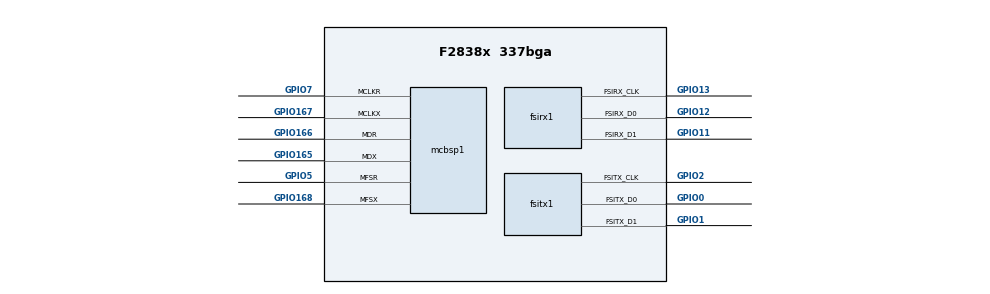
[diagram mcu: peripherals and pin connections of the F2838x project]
/**
 * @cliArgs --device "F2838x" --part "F2838x_337bga" --package "337bga" --context "CPU2" --product "C2000WARE@5.04.00.00"
 * @versions {"tool":"1.21.0+3721"}
 */

/**
 * Import the modules used in this configuration.
 */
const cputimer  = scripting.addModule("/driverlib/cputimer.js", {}, false);
const cputimer1 = cputimer.addInstance();
const dma       = scripting.addModule("/driverlib/dma.js", {}, false);
const dma1      = dma.addInstance();
const dma2      = dma.addInstance();
const flash     = scripting.addModule("/driverlib/flash.js", {}, false);
const flash1    = flash.addInstance();
const fsirx     = scripting.addModule("/driverlib/fsirx.js", {}, false);
const fsirx1    = fsirx.addInstance();
const fsitx     = scripting.addModule("/driverlib/fsitx.js", {}, false);
const fsitx1    = fsitx.addInstance();
const ipc       = scripting.addModule("/driverlib/ipc.js");
const mcbsp     = scripting.addModule("/driverlib/mcbsp.js", {}, false);
const mcbsp1    = mcbsp.addInstance();

/**
 * Write custom configuration values to the imported modules.
 */
cputimer1.$name          = "SWTIRMER";
cputimer1.cputimerBase   = "CPUTIMER1_BASE";
cputimer1.emulationMode  = "CPUTIMER_EMULATIONMODE_RUNFREE";
cputimer1.timerPrescaler = 3;
cputimer1.timerPeriod    = 50000000;
cputimer1.startTimer     = true;

dma1.$name = "DMA_FSI_TX";

dma2.$name   = "DMA_FSI_RX";
dma2.dmaBase = "DMA_CH2_BASE";

flash1.$name = "FMC_CPU2";

fsirx1.$name                      = "FSI_DAISY_RX";
fsirx1.dataWidth                  = "FSI_DATA_WIDTH_2_LANE";
fsirx1.softwareFrameSize          = "14";
fsirx1.fsirx.$assign              = "FSIRXA";
fsirx1.fsirx.fsirx_d0Pin.$assign  = "GPIO12";
fsirx1.fsirx.fsirx_d1Pin.$assign  = "GPIO11";
fsirx1.fsirx.fsirx_clkPin.$assign = "GPIO13";
fsirx1.d0Qual.$name               = "myGPIOQUAL4";
fsirx1.d1Qual.$name               = "myGPIOQUAL5";
fsirx1.clkQual.$name              = "myGPIOQUAL14";

fsitx1.$name                      = "FSI_DAISY_TX";
fsitx1.dataWidth                  = "FSI_DATA_WIDTH_2_LANE";
fsitx1.softwareFrameSize          = "14";
fsitx1.clkPres                    = 2;
fsitx1.fsitx.fsitx_d0Pin.$assign  = "GPIO0";
fsitx1.fsitx.fsitx_d1Pin.$assign  = "GPIO1";
fsitx1.fsitx.fsitx_clkPin.$assign = "GPIO2";
fsitx1.d0Qual.$name               = "myGPIOQUAL15";
fsitx1.d1Qual.$name               = "myGPIOQUAL16";
fsitx1.clkQual.$name              = "myGPIOQUAL17";

ipc.ipcRegisterFlag = ["IPC_FLAG31"];
ipc.flagHandler31   = "IPC_SYNC";

mcbsp1.$name                     = "McBSPA_CVAD_CCDA";
mcbsp1.txClockSource             = "MCBSP_INTERNAL_TX_CLOCK_SOURCE";
mcbsp1.txFrameSyncSource         = "MCBSP_TX_INTERNAL_FRAME_SYNC_SOURCE";
mcbsp1.txFrameSyncPolarity       = "MCBSP_TX_FRAME_SYNC_POLARITY_LOW";
mcbsp1.txDataDelayBits           = "MCBSP_DATA_DELAY_BIT_1";
mcbsp1.rxDataDelayBits           = "MCBSP_DATA_DELAY_BIT_1";
mcbsp1.clockStopMode             = "MCBSP_CLOCK_SPI_MODE_NO_DELAY";
mcbsp1.emulationMode             = "MCBSP_EMULATION_FREE_RUN";
mcbsp1.enableSampleRateGenerator = true;
mcbsp1.enableReceiver            = true;
mcbsp1.enableTransmitter         = true;
mcbsp1.srgDataClockDivider       = 7;
mcbsp1.enableSRGSyncFSR          = true;
mcbsp1.mcbsp.$assign             = "MCBSPA";
mcbsp1.mcbsp.mdxPin.$assign      = "GPIO165";
mcbsp1.mcbsp.mdrPin.$assign      = "GPIO166";
mcbsp1.mcbsp.mclkxPin.$assign    = "GPIO167";
mcbsp1.mcbsp.mclkrPin.$assign    = "GPIO7";
mcbsp1.mcbsp.mfsxPin.$assign     = "GPIO168";
mcbsp1.mcbsp.mfsrPin.$assign     = "GPIO5";

/**
 * Pinmux solution for unlocked pins/peripherals. This ensures that minor changes to the automatic solver in a future
 * version of the tool will not impact the pinmux you originally saw.  These lines can be completely deleted in order to
 * re-solve from scratch.
 */
fsitx1.fsitx.$suggestSolution = "FSITXA";
